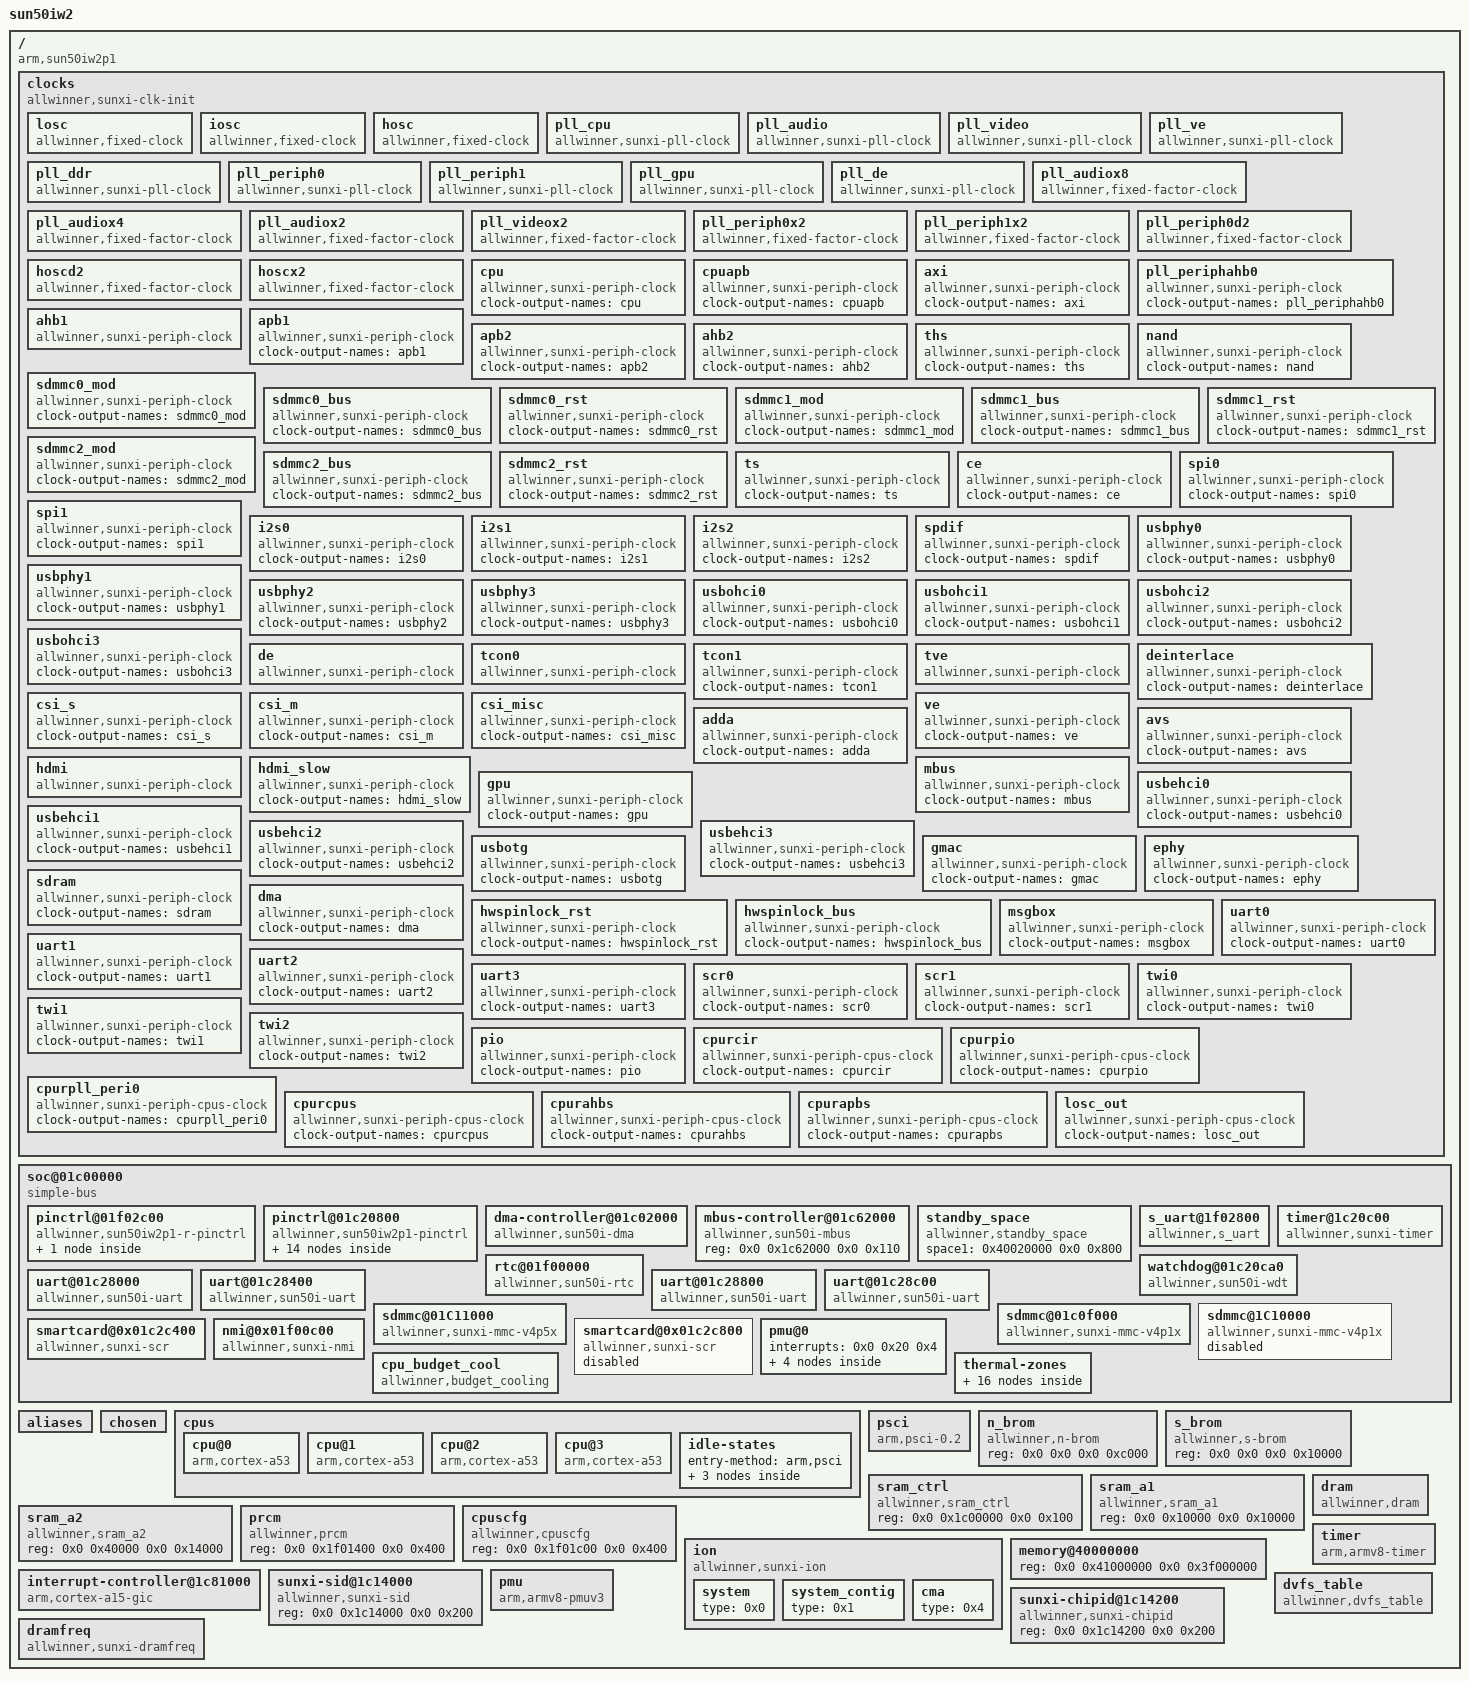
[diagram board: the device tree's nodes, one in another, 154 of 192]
/dts-v1/;

/memreserve/	0x0000000040020000 0x0000000000000800;
/memreserve/	0x0000000048000000 0x0000000001000000;
/memreserve/	0x0000000048100000 0x0000000000004000;
/memreserve/	0x0000000048104000 0x0000000000001000;
/memreserve/	0x0000000048105000 0x0000000000001000;
/ {
	model = "sun50iw2";
	compatible = "arm,sun50iw2p1";
	interrupt-parent = <0x1>;
	#address-cells = <0x2>;
	#size-cells = <0x2>;

	clocks {
		compatible = "allwinner,sunxi-clk-init";
		device_type = "clocks";
		#address-cells = <0x2>;
		#size-cells = <0x2>;
		ranges;
		reg = <0x0 0x1c20000 0x0 0x324 0x0 0x1f01400 0x0 0x1d4 0x0 0x1f00060 0x0 0x4>;

		losc {
			#clock-cells = <0x0>;
			compatible = "allwinner,fixed-clock";
			clock-frequency = <0x8000>;
			clock-output-names = "losc";
			linux,phandle = <0xb>;
			phandle = <0xb>;
		};

		iosc {
			#clock-cells = <0x0>;
			compatible = "allwinner,fixed-clock";
			clock-frequency = <0xf42400>;
			clock-output-names = "iosc";
			linux,phandle = <0xc>;
			phandle = <0xc>;
		};

		hosc {
			#clock-cells = <0x0>;
			compatible = "allwinner,fixed-clock";
			clock-frequency = <0x16e3600>;
			clock-output-names = "hosc";
			linux,phandle = <0x6>;
			phandle = <0x6>;
		};

		pll_cpu {
			#clock-cells = <0x0>;
			compatible = "allwinner,sunxi-pll-clock";
			lock-mode = "none";
			clock-output-names = "pll_cpu";
		};

		pll_audio {
			#clock-cells = <0x0>;
			compatible = "allwinner,sunxi-pll-clock";
			lock-mode = "none";
			assigned-clock-rates = <0x1770000>;
			clock-output-names = "pll_audio";
			linux,phandle = <0x2>;
			phandle = <0x2>;
		};

		pll_video {
			#clock-cells = <0x0>;
			compatible = "allwinner,sunxi-pll-clock";
			lock-mode = "none";
			assigned-clock-rates = <0x11b3dc40>;
			clock-output-names = "pll_video";
			linux,phandle = <0x3>;
			phandle = <0x3>;
		};

		pll_ve {
			#clock-cells = <0x0>;
			compatible = "allwinner,sunxi-pll-clock";
			device_type = "clk_pll_ve";
			lock-mode = "none";
			assigned-clock-rates = <0x1908b100>;
			clock-output-names = "pll_ve";
			linux,phandle = <0x15>;
			phandle = <0x15>;
		};

		pll_ddr {
			#clock-cells = <0x0>;
			compatible = "allwinner,sunxi-pll-clock";
			lock-mode = "none";
			clock-output-names = "pll_ddr";
			linux,phandle = <0x99>;
			phandle = <0x99>;
		};

		pll_periph0 {
			#clock-cells = <0x0>;
			compatible = "allwinner,sunxi-pll-clock";
			lock-mode = "none";
			clock-output-names = "pll_periph0";
			linux,phandle = <0x4>;
			phandle = <0x4>;
		};

		pll_periph1 {
			#clock-cells = <0x0>;
			compatible = "allwinner,sunxi-pll-clock";
			lock-mode = "none";
			clock-output-names = "pll_periph1";
			linux,phandle = <0x5>;
			phandle = <0x5>;
		};

		pll_gpu {
			#clock-cells = <0x0>;
			compatible = "allwinner,sunxi-pll-clock";
			lock-mode = "none";
			clock-output-names = "pll_gpu";
		};

		pll_de {
			#clock-cells = <0x0>;
			compatible = "allwinner,sunxi-pll-clock";
			lock-mode = "none";
			assigned-clock-rates = <0x337f9800>;
			clock-output-names = "pll_de";
			linux,phandle = <0x7>;
			phandle = <0x7>;
		};

		pll_audiox8 {
			#clock-cells = <0x0>;
			compatible = "allwinner,fixed-factor-clock";
			clocks = <0x2>;
			clock-mult = <0x8>;
			clock-div = <0x1>;
			clock-output-names = "pll_audiox8";
		};

		pll_audiox4 {
			#clock-cells = <0x0>;
			compatible = "allwinner,fixed-factor-clock";
			clocks = <0x2>;
			clock-mult = <0x8>;
			clock-div = <0x2>;
			clock-output-names = "pll_audiox4";
		};

		pll_audiox2 {
			#clock-cells = <0x0>;
			compatible = "allwinner,fixed-factor-clock";
			clocks = <0x2>;
			clock-mult = <0x8>;
			clock-div = <0x4>;
			clock-output-names = "pll_audiox2";
		};

		pll_videox2 {
			#clock-cells = <0x0>;
			compatible = "allwinner,fixed-factor-clock";
			clocks = <0x3>;
			clock-mult = <0x2>;
			clock-div = <0x1>;
			clock-output-names = "pll_videox2";
		};

		pll_periph0x2 {
			#clock-cells = <0x0>;
			compatible = "allwinner,fixed-factor-clock";
			clocks = <0x4>;
			clock-mult = <0x2>;
			clock-div = <0x1>;
			clock-output-names = "pll_periph0x2";
		};

		pll_periph1x2 {
			#clock-cells = <0x0>;
			compatible = "allwinner,fixed-factor-clock";
			clocks = <0x5>;
			clock-mult = <0x2>;
			clock-div = <0x1>;
			clock-output-names = "pll_periph1x2";
			linux,phandle = <0x52>;
			phandle = <0x52>;
		};

		pll_periph0d2 {
			#clock-cells = <0x0>;
			compatible = "allwinner,fixed-factor-clock";
			clocks = <0x4>;
			clock-mult = <0x1>;
			clock-div = <0x2>;
			clock-output-names = "pll_periph0d2";
		};

		hoscd2 {
			#clock-cells = <0x0>;
			compatible = "allwinner,fixed-factor-clock";
			clocks = <0x6>;
			clock-mult = <0x1>;
			clock-div = <0x2>;
			clock-output-names = "hoscd2";
		};

		hoscx2 {
			#clock-cells = <0x0>;
			compatible = "allwinner,fixed-factor-clock";
			clocks = <0x6>;
			clock-mult = <0x2>;
			clock-div = <0x1>;
			clock-output-names = "hoscx2";
		};

		cpu {
			#clock-cells = <0x0>;
			compatible = "allwinner,sunxi-periph-clock";
			clock-output-names = "cpu";
		};

		cpuapb {
			#clock-cells = <0x0>;
			compatible = "allwinner,sunxi-periph-clock";
			clock-output-names = "cpuapb";
		};

		axi {
			#clock-cells = <0x0>;
			compatible = "allwinner,sunxi-periph-clock";
			clock-output-names = "axi";
		};

		pll_periphahb0 {
			#clock-cells = <0x0>;
			compatible = "allwinner,sunxi-periph-clock";
			clock-output-names = "pll_periphahb0";
		};

		ahb1 {
			#clock-cells = <0x0>;
			assigned-clock-rates = <0xbebc200>;
			compatible = "allwinner,sunxi-periph-clock";
			clock-output-names = "ahb1";
			linux,phandle = <0x9a>;
			phandle = <0x9a>;
		};

		apb1 {
			#clock-cells = <0x0>;
			compatible = "allwinner,sunxi-periph-clock";
			clock-output-names = "apb1";
		};

		apb2 {
			#clock-cells = <0x0>;
			compatible = "allwinner,sunxi-periph-clock";
			clock-output-names = "apb2";
			linux,phandle = <0x74>;
			phandle = <0x74>;
		};

		ahb2 {
			#clock-cells = <0x0>;
			compatible = "allwinner,sunxi-periph-clock";
			clock-output-names = "ahb2";
		};

		ths {
			#clock-cells = <0x0>;
			compatible = "allwinner,sunxi-periph-clock";
			clock-output-names = "ths";
			linux,phandle = <0x89>;
			phandle = <0x89>;
		};

		nand {
			#clock-cells = <0x0>;
			compatible = "allwinner,sunxi-periph-clock";
			clock-output-names = "nand";
			linux,phandle = <0x7c>;
			phandle = <0x7c>;
		};

		sdmmc0_mod {
			#clock-cells = <0x0>;
			compatible = "allwinner,sunxi-periph-clock";
			clock-output-names = "sdmmc0_mod";
			linux,phandle = <0x58>;
			phandle = <0x58>;
		};

		sdmmc0_bus {
			#clock-cells = <0x0>;
			compatible = "allwinner,sunxi-periph-clock";
			clock-output-names = "sdmmc0_bus";
			linux,phandle = <0x59>;
			phandle = <0x59>;
		};

		sdmmc0_rst {
			#clock-cells = <0x0>;
			compatible = "allwinner,sunxi-periph-clock";
			clock-output-names = "sdmmc0_rst";
			linux,phandle = <0x5a>;
			phandle = <0x5a>;
		};

		sdmmc1_mod {
			#clock-cells = <0x0>;
			compatible = "allwinner,sunxi-periph-clock";
			clock-output-names = "sdmmc1_mod";
			linux,phandle = <0x5e>;
			phandle = <0x5e>;
		};

		sdmmc1_bus {
			#clock-cells = <0x0>;
			compatible = "allwinner,sunxi-periph-clock";
			clock-output-names = "sdmmc1_bus";
			linux,phandle = <0x5f>;
			phandle = <0x5f>;
		};

		sdmmc1_rst {
			#clock-cells = <0x0>;
			compatible = "allwinner,sunxi-periph-clock";
			clock-output-names = "sdmmc1_rst";
			linux,phandle = <0x60>;
			phandle = <0x60>;
		};

		sdmmc2_mod {
			#clock-cells = <0x0>;
			compatible = "allwinner,sunxi-periph-clock";
			clock-output-names = "sdmmc2_mod";
			linux,phandle = <0x53>;
			phandle = <0x53>;
		};

		sdmmc2_bus {
			#clock-cells = <0x0>;
			compatible = "allwinner,sunxi-periph-clock";
			clock-output-names = "sdmmc2_bus";
			linux,phandle = <0x54>;
			phandle = <0x54>;
		};

		sdmmc2_rst {
			#clock-cells = <0x0>;
			compatible = "allwinner,sunxi-periph-clock";
			clock-output-names = "sdmmc2_rst";
			linux,phandle = <0x55>;
			phandle = <0x55>;
		};

		ts {
			#clock-cells = <0x0>;
			compatible = "allwinner,sunxi-periph-clock";
			clock-output-names = "ts";
			linux,phandle = <0x80>;
			phandle = <0x80>;
		};

		ce {
			#clock-cells = <0x0>;
			compatible = "allwinner,sunxi-periph-clock";
			clock-output-names = "ce";
			linux,phandle = <0x71>;
			phandle = <0x71>;
		};

		spi0 {
			#clock-cells = <0x0>;
			compatible = "allwinner,sunxi-periph-clock";
			clock-output-names = "spi0";
			linux,phandle = <0x4a>;
			phandle = <0x4a>;
		};

		spi1 {
			#clock-cells = <0x0>;
			compatible = "allwinner,sunxi-periph-clock";
			clock-output-names = "spi1";
			linux,phandle = <0x4e>;
			phandle = <0x4e>;
		};

		i2s0 {
			#clock-cells = <0x0>;
			compatible = "allwinner,sunxi-periph-clock";
			clock-output-names = "i2s0";
			linux,phandle = <0x3a>;
			phandle = <0x3a>;
		};

		i2s1 {
			#clock-cells = <0x0>;
			compatible = "allwinner,sunxi-periph-clock";
			clock-output-names = "i2s1";
			linux,phandle = <0x3f>;
			phandle = <0x3f>;
		};

		i2s2 {
			#clock-cells = <0x0>;
			compatible = "allwinner,sunxi-periph-clock";
			clock-output-names = "i2s2";
			linux,phandle = <0x40>;
			phandle = <0x40>;
		};

		spdif {
			#clock-cells = <0x0>;
			compatible = "allwinner,sunxi-periph-clock";
			clock-output-names = "spdif";
			linux,phandle = <0x41>;
			phandle = <0x41>;
		};

		usbphy0 {
			#clock-cells = <0x0>;
			compatible = "allwinner,sunxi-periph-clock";
			clock-output-names = "usbphy0";
			linux,phandle = <0x2c>;
			phandle = <0x2c>;
		};

		usbphy1 {
			#clock-cells = <0x0>;
			compatible = "allwinner,sunxi-periph-clock";
			clock-output-names = "usbphy1";
			linux,phandle = <0x30>;
			phandle = <0x30>;
		};

		usbphy2 {
			#clock-cells = <0x0>;
			compatible = "allwinner,sunxi-periph-clock";
			clock-output-names = "usbphy2";
			linux,phandle = <0x33>;
			phandle = <0x33>;
		};

		usbphy3 {
			#clock-cells = <0x0>;
			compatible = "allwinner,sunxi-periph-clock";
			clock-output-names = "usbphy3";
			linux,phandle = <0x36>;
			phandle = <0x36>;
		};

		usbohci0 {
			#clock-cells = <0x0>;
			compatible = "allwinner,sunxi-periph-clock";
			clock-output-names = "usbohci0";
			linux,phandle = <0x2f>;
			phandle = <0x2f>;
		};

		usbohci1 {
			#clock-cells = <0x0>;
			compatible = "allwinner,sunxi-periph-clock";
			clock-output-names = "usbohci1";
			linux,phandle = <0x32>;
			phandle = <0x32>;
		};

		usbohci2 {
			#clock-cells = <0x0>;
			compatible = "allwinner,sunxi-periph-clock";
			clock-output-names = "usbohci2";
			linux,phandle = <0x35>;
			phandle = <0x35>;
		};

		usbohci3 {
			#clock-cells = <0x0>;
			compatible = "allwinner,sunxi-periph-clock";
			clock-output-names = "usbohci3";
			linux,phandle = <0x38>;
			phandle = <0x38>;
		};

		de {
			#clock-cells = <0x0>;
			compatible = "allwinner,sunxi-periph-clock";
			assigned-clock-parents = <0x7>;
			assigned-clock-rates = <0x19bfcc00>;
			clock-output-names = "de";
			linux,phandle = <0x63>;
			phandle = <0x63>;
		};

		tcon0 {
			#clock-cells = <0x0>;
			compatible = "allwinner,sunxi-periph-clock";
			assigned-clock-parents = <0x3>;
			clock-output-names = "tcon0";
			linux,phandle = <0x64>;
			phandle = <0x64>;
		};

		tcon1 {
			#clock-cells = <0x0>;
			compatible = "allwinner,sunxi-periph-clock";
			clock-output-names = "tcon1";
			linux,phandle = <0x65>;
			phandle = <0x65>;
		};

		tve {
			#clock-cells = <0x0>;
			compatible = "allwinner,sunxi-periph-clock";
			assigned-clock-parents = <0x7>;
			clock-output-names = "tve";
			linux,phandle = <0x68>;
			phandle = <0x68>;
		};

		deinterlace {
			#clock-cells = <0x0>;
			compatible = "allwinner,sunxi-periph-clock";
			clock-output-names = "deinterlace";
			linux,phandle = <0x72>;
			phandle = <0x72>;
		};

		csi_s {
			#clock-cells = <0x0>;
			compatible = "allwinner,sunxi-periph-clock";
			clock-output-names = "csi_s";
			linux,phandle = <0x6b>;
			phandle = <0x6b>;
		};

		csi_m {
			#clock-cells = <0x0>;
			compatible = "allwinner,sunxi-periph-clock";
			clock-output-names = "csi_m";
			linux,phandle = <0x6c>;
			phandle = <0x6c>;
		};

		csi_misc {
			#clock-cells = <0x0>;
			compatible = "allwinner,sunxi-periph-clock";
			clock-output-names = "csi_misc";
			linux,phandle = <0x6d>;
			phandle = <0x6d>;
		};

		ve {
			#clock-cells = <0x0>;
			compatible = "allwinner,sunxi-periph-clock";
			clock-output-names = "ve";
			linux,phandle = <0x16>;
			phandle = <0x16>;
		};

		adda {
			#clock-cells = <0x0>;
			compatible = "allwinner,sunxi-periph-clock";
			clock-output-names = "adda";
			linux,phandle = <0x39>;
			phandle = <0x39>;
		};

		avs {
			#clock-cells = <0x0>;
			compatible = "allwinner,sunxi-periph-clock";
			clock-output-names = "avs";
		};

		hdmi {
			#clock-cells = <0x0>;
			compatible = "allwinner,sunxi-periph-clock";
			assigned-clock-parents = <0x3>;
			clock-output-names = "hdmi";
			linux,phandle = <0x66>;
			phandle = <0x66>;
		};

		hdmi_slow {
			#clock-cells = <0x0>;
			compatible = "allwinner,sunxi-periph-clock";
			clock-output-names = "hdmi_slow";
			linux,phandle = <0x67>;
			phandle = <0x67>;
		};

		mbus {
			#clock-cells = <0x0>;
			compatible = "allwinner,sunxi-periph-clock";
			clock-output-names = "mbus";
		};

		gpu {
			#clock-cells = <0x0>;
			compatible = "allwinner,sunxi-periph-clock";
			clock-output-names = "gpu";
		};

		usbehci0 {
			#clock-cells = <0x0>;
			compatible = "allwinner,sunxi-periph-clock";
			clock-output-names = "usbehci0";
			linux,phandle = <0x2e>;
			phandle = <0x2e>;
		};

		usbehci1 {
			#clock-cells = <0x0>;
			compatible = "allwinner,sunxi-periph-clock";
			clock-output-names = "usbehci1";
			linux,phandle = <0x31>;
			phandle = <0x31>;
		};

		usbehci2 {
			#clock-cells = <0x0>;
			compatible = "allwinner,sunxi-periph-clock";
			clock-output-names = "usbehci2";
			linux,phandle = <0x34>;
			phandle = <0x34>;
		};

		usbehci3 {
			#clock-cells = <0x0>;
			compatible = "allwinner,sunxi-periph-clock";
			clock-output-names = "usbehci3";
			linux,phandle = <0x37>;
			phandle = <0x37>;
		};

		usbotg {
			#clock-cells = <0x0>;
			compatible = "allwinner,sunxi-periph-clock";
			clock-output-names = "usbotg";
			linux,phandle = <0x2d>;
			phandle = <0x2d>;
		};

		gmac {
			#clock-cells = <0x0>;
			compatible = "allwinner,sunxi-periph-clock";
			clock-output-names = "gmac";
			linux,phandle = <0x94>;
			phandle = <0x94>;
		};

		ephy {
			#clock-cells = <0x0>;
			compatible = "allwinner,sunxi-periph-clock";
			clock-output-names = "ephy";
			linux,phandle = <0x95>;
			phandle = <0x95>;
		};

		sdram {
			#clock-cells = <0x0>;
			compatible = "allwinner,sunxi-periph-clock";
			clock-output-names = "sdram";
		};

		dma {
			#clock-cells = <0x0>;
			compatible = "allwinner,sunxi-periph-clock";
			clock-output-names = "dma";
			linux,phandle = <0xa>;
			phandle = <0xa>;
		};

		hwspinlock_rst {
			#clock-cells = <0x0>;
			compatible = "allwinner,sunxi-periph-clock";
			clock-output-names = "hwspinlock_rst";
			linux,phandle = <0xe>;
			phandle = <0xe>;
		};

		hwspinlock_bus {
			#clock-cells = <0x0>;
			compatible = "allwinner,sunxi-periph-clock";
			clock-output-names = "hwspinlock_bus";
			linux,phandle = <0xf>;
			phandle = <0xf>;
		};

		msgbox {
			#clock-cells = <0x0>;
			compatible = "allwinner,sunxi-periph-clock";
			clock-output-names = "msgbox";
			linux,phandle = <0xd>;
			phandle = <0xd>;
		};

		uart0 {
			#clock-cells = <0x0>;
			compatible = "allwinner,sunxi-periph-clock";
			clock-output-names = "uart0";
			linux,phandle = <0x17>;
			phandle = <0x17>;
		};

		uart1 {
			#clock-cells = <0x0>;
			compatible = "allwinner,sunxi-periph-clock";
			clock-output-names = "uart1";
			linux,phandle = <0x1a>;
			phandle = <0x1a>;
		};

		uart2 {
			#clock-cells = <0x0>;
			compatible = "allwinner,sunxi-periph-clock";
			clock-output-names = "uart2";
			linux,phandle = <0x1d>;
			phandle = <0x1d>;
		};

		uart3 {
			#clock-cells = <0x0>;
			compatible = "allwinner,sunxi-periph-clock";
			clock-output-names = "uart3";
			linux,phandle = <0x20>;
			phandle = <0x20>;
		};

		scr0 {
			#clock-cells = <0x0>;
			compatible = "allwinner,sunxi-periph-clock";
			clock-output-names = "scr0";
			linux,phandle = <0x73>;
			phandle = <0x73>;
		};

		scr1 {
			#clock-cells = <0x0>;
			compatible = "allwinner,sunxi-periph-clock";
			clock-output-names = "scr1";
			linux,phandle = <0x78>;
			phandle = <0x78>;
		};

		twi0 {
			#clock-cells = <0x0>;
			compatible = "allwinner,sunxi-periph-clock";
			clock-output-names = "twi0";
			linux,phandle = <0x23>;
			phandle = <0x23>;
		};

		twi1 {
			#clock-cells = <0x0>;
			compatible = "allwinner,sunxi-periph-clock";
			clock-output-names = "twi1";
			linux,phandle = <0x26>;
			phandle = <0x26>;
		};

		twi2 {
			#clock-cells = <0x0>;
			compatible = "allwinner,sunxi-periph-clock";
			clock-output-names = "twi2";
			linux,phandle = <0x29>;
			phandle = <0x29>;
		};

		pio {
			#clock-cells = <0x0>;
			compatible = "allwinner,sunxi-periph-clock";
			clock-output-names = "pio";
			linux,phandle = <0x9>;
			phandle = <0x9>;
		};

		cpurcir {
			#clock-cells = <0x0>;
			compatible = "allwinner,sunxi-periph-cpus-clock";
			clock-output-names = "cpurcir";
			linux,phandle = <0x11>;
			phandle = <0x11>;
		};

		cpurpio {
			#clock-cells = <0x0>;
			compatible = "allwinner,sunxi-periph-cpus-clock";
			clock-output-names = "cpurpio";
			linux,phandle = <0x8>;
			phandle = <0x8>;
		};

		cpurpll_peri0 {
			#clock-cells = <0x0>;
			compatible = "allwinner,sunxi-periph-cpus-clock";
			clock-output-names = "cpurpll_peri0";
		};

		cpurcpus {
			#clock-cells = <0x0>;
			compatible = "allwinner,sunxi-periph-cpus-clock";
			clock-output-names = "cpurcpus";
		};

		cpurahbs {
			#clock-cells = <0x0>;
			compatible = "allwinner,sunxi-periph-cpus-clock";
			clock-output-names = "cpurahbs";
		};

		cpurapbs {
			#clock-cells = <0x0>;
			compatible = "allwinner,sunxi-periph-cpus-clock";
			clock-output-names = "cpurapbs";
		};

		losc_out {
			#clock-cells = <0x0>;
			compatible = "allwinner,sunxi-periph-cpus-clock";
			clock-output-names = "losc_out";
			linux,phandle = <0x9b>;
			phandle = <0x9b>;
		};
	};

	soc@01c00000 {
		compatible = "simple-bus";
		#address-cells = <0x2>;
		#size-cells = <0x2>;
		ranges;
		device_type = "soc";

		pinctrl@01f02c00 {
			compatible = "allwinner,sun50iw2p1-r-pinctrl";
			reg = <0x0 0x1f02c00 0x0 0x400>;
			interrupts = <0x0 0x2d 0x4>;
			clocks = <0x8>;
			device_type = "r_pio";
			gpio-controller;
			interrupt-controller;
			#interrupt-cells = <0x2>;
			#size-cells = <0x0>;
			#gpio-cells = <0x6>;
			linux,phandle = <0x9c>;
			phandle = <0x9c>;

			s_uart0@0 {
				allwinner,pins = "PL2", "PL3";
				allwinner,function = "s_uart0";
				allwinner,muxsel = <0x2>;
				allwinner,drive = <0x1>;
				allwinner,pull = <0x1>;
				linux,phandle = <0x12>;
				phandle = <0x12>;
			};
		};

		pinctrl@01c20800 {
			compatible = "allwinner,sun50iw2p1-pinctrl";
			reg = <0x0 0x1c20800 0x0 0x400>;
			interrupts = <0x0 0xb 0x4 0x0 0x11 0x4 0x0 0x17 0x4>;
			device_type = "pio";
			clocks = <0x9>;
			gpio-controller;
			interrupt-controller;
			#interrupt-cells = <0x2>;
			#size-cells = <0x0>;
			#gpio-cells = <0x6>;
			linux,phandle = <0x5d>;
			phandle = <0x5d>;

			uart0@0 {
				allwinner,pins = "PA4", "PA5";
				allwinner,pname = "uart0_tx", "uart0_rx";
				allwinner,function = "uart0";
				allwinner,muxsel = <0x2>;
				allwinner,drive = <0x1>;
				allwinner,pull = <0x1>;
				linux,phandle = <0x18>;
				phandle = <0x18>;
			};

			uart0@1 {
				allwinner,pins = "PA4", "PA5";
				allwinner,function = "io_disabled";
				allwinner,muxsel = <0x7>;
				allwinner,drive = <0x1>;
				allwinner,pull = <0x0>;
				linux,phandle = <0x19>;
				phandle = <0x19>;
			};

			uart1@0 {
				allwinner,pins = "PG6", "PG7", "PG8", "PG9";
				allwinner,pname = "uart1_tx", "uart1_rx", "uart1_rts", "uart1_cts";
				allwinner,function = "uart1";
				allwinner,muxsel = <0x2>;
				allwinner,drive = <0x1>;
				allwinner,pull = <0x1>;
				linux,phandle = <0x1b>;
				phandle = <0x1b>;
			};

			uart1@1 {
				allwinner,pins = "PG6", "PG7", "PG8", "PG9";
				allwinner,function = "io_disabled";
				allwinner,muxsel = <0x7>;
				allwinner,drive = <0x1>;
				allwinner,pull = <0x0>;
				linux,phandle = <0x1c>;
				phandle = <0x1c>;
			};

			uart2@0 {
				allwinner,pins = "PA0", "PA1", "PA2", "PA3";
				allwinner,pname = "uart2_tx", "uart2_rx", "uart2_rts", "uart2_cts";
				allwinner,function = "uart2";
				allwinner,muxsel = <0x2>;
				allwinner,drive = <0x1>;
				allwinner,pull = <0x1>;
				linux,phandle = <0x1e>;
				phandle = <0x1e>;
			};

			uart2@1 {
				allwinner,pins = "PA0", "PA1", "PA2", "PA3";
				allwinner,function = "io_disabled";
				allwinner,muxsel = <0x7>;
				allwinner,drive = <0x1>;
				allwinner,pull = <0x0>;
				linux,phandle = <0x1f>;
				phandle = <0x1f>;
			};

			uart3@0 {
				allwinner,pins = "PA13", "PA14";
				allwinner,pname = "uart3_tx", "uart3_rx";
				allwinner,function = "uart3";
				allwinner,muxsel = <0x3>;
				allwinner,drive = <0x1>;
				allwinner,pull = <0x1>;
				linux,phandle = <0x21>;
				phandle = <0x21>;
			};

			uart3@1 {
				allwinner,pins = "PA13", "PA14", "PA15", "PA16";
				allwinner,function = "io_disabled";
				allwinner,muxsel = <0x7>;
				allwinner,drive = <0x1>;
				allwinner,pull = <0x0>;
				linux,phandle = <0x22>;
				phandle = <0x22>;
			};

			sdc0@0 {
				allwinner,pins = "PF0", "PF1", "PF2", "PF3", "PF4", "PF5";
				allwinner,function = "sdc0";
				allwinner,muxsel = <0x2>;
				allwinner,drive = <0x1>;
				allwinner,pull = <0x1>;
				linux,phandle = <0x5b>;
				phandle = <0x5b>;
			};

			sdc0@1 {
				allwinner,pins = "PF0", "PF1", "PF2", "PF3", "PF4", "PF5";
				allwinner,function = "io_disabled";
				allwinner,muxsel = <0x7>;
				allwinner,drive = <0x1>;
				allwinner,pull = <0x1>;
				linux,phandle = <0x5c>;
				phandle = <0x5c>;
			};

			sdc1@0 {
				allwinner,pins = "PG0", "PG1", "PG2", "PG3", "PG4", "PG5";
				allwinner,function = "sdc1";
				allwinner,muxsel = <0x2>;
				allwinner,drive = <0x3>;
				allwinner,pull = <0x1>;
				linux,phandle = <0x61>;
				phandle = <0x61>;
			};

			sdc1@1 {
				allwinner,pins = "PG0", "PG1", "PG2", "PG3", "PG4", "PG5";
				allwinner,function = "io_disabled";
				allwinner,muxsel = <0x7>;
				allwinner,drive = <0x1>;
				allwinner,pull = <0x1>;
				linux,phandle = <0x62>;
				phandle = <0x62>;
			};

			sdc2@0 {
				allwinner,pins = "PC1", "PC5", "PC6", "PC8", "PC9", "PC10", "PC11", "PC12", "PC13", "PC14", "PC15", "PC16";
				allwinner,function = "sdc2";
				allwinner,muxsel = <0x3>;
				allwinner,drive = <0x2>;
				allwinner,pull = <0x1>;
				linux,phandle = <0x56>;
				phandle = <0x56>;
			};

			sdc2@1 {
				allwinner,pins = "PC1", "PC5", "PC6", "PC8", "PC9", "PC10", "PC11", "PC12", "PC13", "PC14", "PC15", "PC16";
				allwinner,function = "io_disabled";
				allwinner,muxsel = <0x7>;
				allwinner,drive = <0x1>;
				allwinner,pull = <0x1>;
				linux,phandle = <0x57>;
				phandle = <0x57>;
			};
		};

		dma-controller@01c02000 {
			compatible = "allwinner,sun50i-dma";
			reg = <0x0 0x1c02000 0x0 0x1000>;
			interrupts = <0x0 0x32 0x4>;
			clocks = <0xa>;
			#dma-cells = <0x1>;
		};

		mbus-controller@01c62000 {
			compatible = "allwinner,sun50i-mbus";
			reg = <0x0 0x1c62000 0x0 0x110>;
			#mbus-cells = <0x1>;
		};

		standby_space {
			compatible = "allwinner,standby_space";
			space1 = <0x40020000 0x0 0x800>;
		};

		s_uart@1f02800 {
			compatible = "allwinner,s_uart";
			reg = <0x0 0x1f02800 0x0 0x400>;
			interrupts = <0x0 0x26 0x4>;
			pinctrl-names = "default";
			pinctrl-0 = <0x12>;
			status = "okay";
		};

		timer@1c20c00 {
			compatible = "allwinner,sunxi-timer";
			device_type = "timer";
			reg = <0x0 0x1c20c00 0x0 0x90>;
			interrupts = <0x0 0x12 0x1>;
			clock-frequency = <0x16e3600>;
			timer-prescale = <0x10>;
		};

		rtc@01f00000 {
			compatible = "allwinner,sun50i-rtc";
			device_type = "rtc";
			reg = <0x0 0x1f00000 0x0 0x218>;
			interrupts = <0x0 0x28 0x4>;
			gpr_offset = <0x100>;
			gpr_len = <0x4>;
		};

		watchdog@01c20ca0 {
			compatible = "allwinner,sun50i-wdt";
			reg = <0x0 0x1c20ca0 0x0 0x20>;
			interrupts = <0x0 0x19 0x4>;
		};

		uart@01c28000 {
			compatible = "allwinner,sun50i-uart";
			device_type = "uart0";
			reg = <0x0 0x1c28000 0x0 0x400>;
			interrupts = <0x0 0x0 0x4>;
			clocks = <0x17>;
			pinctrl-names = "default", "sleep";
			pinctrl-0 = <0x18>;
			pinctrl-1 = <0x19>;
			uart0_port = <0x0>;
			uart0_type = <0x2>;
			status = "okay";
		};

		uart@01c28400 {
			compatible = "allwinner,sun50i-uart";
			device_type = "uart1";
			reg = <0x0 0x1c28400 0x0 0x400>;
			interrupts = <0x0 0x1 0x4>;
			clocks = <0x1a>;
			pinctrl-names = "default", "sleep";
			pinctrl-0 = <0x1b>;
			pinctrl-1 = <0x1c>;
			uart1_port = <0x1>;
			uart1_type = <0x4>;
			status = "okay";
		};

		uart@01c28800 {
			compatible = "allwinner,sun50i-uart";
			device_type = "uart2";
			reg = <0x0 0x1c28800 0x0 0x400>;
			interrupts = <0x0 0x2 0x4>;
			clocks = <0x1d>;
			pinctrl-names = "default", "sleep";
			pinctrl-0 = <0x1e>;
			pinctrl-1 = <0x1f>;
			uart2_port = <0x2>;
			uart2_type = <0x4>;
			status = "okay";
		};

		uart@01c28c00 {
			compatible = "allwinner,sun50i-uart";
			device_type = "uart3";
			reg = <0x0 0x1c28c00 0x0 0x400>;
			interrupts = <0x0 0x3 0x4>;
			clocks = <0x20>;
			pinctrl-names = "default", "sleep";
			pinctrl-0 = <0x21>;
			pinctrl-1 = <0x22>;
			uart3_port = <0x3>;
			uart3_type = <0x4>;
			status = "okay";
		};

		sdmmc@01C11000 {
			compatible = "allwinner,sunxi-mmc-v4p5x";
			device_type = "sdc2";
			boot_device = <0x0>;
			reg = <0x0 0x1c11000 0x0 0x1000>;
			interrupts = <0x0 0x3e 0x104>;
			clocks = <0x6 0x52 0x53 0x54 0x55>;
			clock-names = "osc24m", "pll_periph", "mmc", "ahb", "rst";
			pinctrl-names = "default", "sleep";
			pinctrl-0 = <0x56>;
			pinctrl-1 = <0x57>;
			bus-width = <0x8>;
			max-frequency = <0x2faf080>;
			sdc_tm4_sm0_freq0 = <0x0>;
			sdc_tm4_sm0_freq1 = <0x0>;
			sdc_tm4_sm1_freq0 = <0x0>;
			sdc_tm4_sm1_freq1 = <0x0>;
			sdc_tm4_sm2_freq0 = <0x0>;
			sdc_tm4_sm2_freq1 = <0x0>;
			sdc_tm4_sm3_freq0 = <0x5000000>;
			sdc_tm4_sm3_freq1 = <0x5>;
			sdc_tm4_sm4_freq0 = <0x50000>;
			sdc_tm4_sm4_freq1 = <0x4>;
			status = "okay";
		};

		sdmmc@01c0f000 {
			compatible = "allwinner,sunxi-mmc-v4p1x";
			device_type = "sdc0";
			boot_device = <0x0>;
			reg = <0x0 0x1c0f000 0x0 0x1000>;
			interrupts = <0x0 0x3c 0x104>;
			clocks = <0x6 0x52 0x58 0x59 0x5a>;
			clock-names = "osc24m", "pll_periph", "mmc", "ahb", "rst";
			pinctrl-names = "default", "sleep";
			pinctrl-0 = <0x5b>;
			pinctrl-1 = <0x5c>;
			max-frequency = <0x2faf080>;
			bus-width = <0x4>;
			cd-gpios = <0x5d 0x5 0x6 0x0 0x1 0x2 0x0>;
			status = "okay";
		};

		sdmmc@1C10000 {
			compatible = "allwinner,sunxi-mmc-v4p1x";
			device_type = "sdc1";
			boot_device = <0x0>;
			reg = <0x0 0x1c10000 0x0 0x1000>;
			interrupts = <0x0 0x3d 0x104>;
			clocks = <0x6 0x52 0x5e 0x5f 0x60>;
			clock-names = "osc24m", "pll_periph", "mmc", "ahb", "rst";
			pinctrl-names = "default", "sleep";
			pinctrl-0 = <0x61>;
			pinctrl-1 = <0x62>;
			max-frequency = <0x2faf080>;
			bus-width = <0x4>;
			sunxi-dly-52M-ddr4 = <0x1 0x0 0x0 0x0 0x2>;
			sunxi-dly-104M = <0x1 0x0 0x0 0x0 0x1>;
			sunxi-dly-208M = <0x1 0x0 0x0 0x0 0x1>;
			status = "disabled";
		};

		smartcard@0x01c2c400 {
			#address-cells = <0x1>;
			#size-cells = <0x0>;
			compatible = "allwinner,sunxi-scr";
			device_type = "scr0";
			reg = <0x0 0x1c2c400 0x0 0x400>;
			interrupts = <0x0 0x53 0x4>;
			clocks = <0x73 0x74>;
			clock-frequency = <0x16e3600>;
			pinctrl-names = "default", "sleep";
			pinctrl-0 = <0x75 0x76>;
			pinctrl-1 = <0x77>;
			status = "okay";
		};

		smartcard@0x01c2c800 {
			#address-cells = <0x1>;
			#size-cells = <0x0>;
			compatible = "allwinner,sunxi-scr";
			device_type = "scr1";
			reg = <0x0 0x1c2c800 0x0 0x400>;
			interrupts = <0x0 0x59 0x4>;
			clocks = <0x78 0x74>;
			clock-frequency = <0x16e3600>;
			pinctrl-names = "default", "sleep";
			pinctrl-0 = <0x79 0x7a>;
			pinctrl-1 = <0x7b>;
			status = "disabled";
		};

		pmu@0 {
			interrupts = <0x0 0x20 0x4>;
			status = "okay";

			powerkey@0 {
				status = "okay";
			};

			regulator@0 {
				status = "okay";
			};

			axp_gpio@0 {
				gpio-controller;
				#size-cells = <0x0>;
				#gpio-cells = <0x6>;
				status = "disabled";
				device_type = "axp_pio";
			};

			charger@0 {
				status = "disabled";
			};
		};

		nmi@0x01f00c00 {
			#address-cells = <0x1>;
			#size-cells = <0x0>;
			compatible = "allwinner,sunxi-nmi";
			reg = <0x0 0x1f00c00 0x0 0x50>;
			nmi_irq_ctrl = <0xc>;
			nmi_irq_en = <0x40>;
			nmi_irq_status = <0x10>;
			nmi_irq_mask = <0x50>;
			status = "okay";
		};

		cpu_budget_cool {
			compatible = "allwinner,budget_cooling";
			#cooling-cells = <0x2>;
			status = "okay";
			state_cnt = <0x5>;
			cluster_num = <0x1>;
			state0 = <0xf6180 0x4>;
			state1 = <0xc7380 0x4>;
			state2 = <0xc7380 0x2>;
			state3 = <0x9e340 0x2>;
			state4 = <0x75300 0x1>;
			linux,phandle = <0x8c>;
			phandle = <0x8c>;
		};

		thermal-zones {

			soc_thermal {
				polling-delay-passive = <0x3e8>;
				polling-delay = <0x2710>;
				thermal-sensors = <0x8a 0x0>;

				trips {

					t0 {
						temperature = <0x3c>;
						type = "passive";
						hysteresis = <0x0>;
						linux,phandle = <0x8b>;
						phandle = <0x8b>;
					};

					t1 {
						temperature = <0x50>;
						type = "passive";
						hysteresis = <0x0>;
						linux,phandle = <0x8d>;
						phandle = <0x8d>;
					};

					t2 {
						temperature = <0x64>;
						type = "passive";
						hysteresis = <0x0>;
						linux,phandle = <0x8e>;
						phandle = <0x8e>;
					};

					t3 {
						temperature = <0x50>;
						type = "passive";
						hysteresis = <0x0>;
						linux,phandle = <0x8f>;
						phandle = <0x8f>;
					};

					t4 {
						temperature = <0x5a>;
						type = "passive";
						hysteresis = <0x0>;
						linux,phandle = <0x91>;
						phandle = <0x91>;
					};

					t5 {
						temperature = <0x64>;
						type = "passive";
						hysteresis = <0x0>;
						linux,phandle = <0x92>;
						phandle = <0x92>;
					};

					t6 {
						temperature = <0x73>;
						type = "critical";
						hysteresis = <0x0>;
					};
				};

				cooling-maps {

					bind0 {
						contribution = <0x0>;
						trip = <0x8b>;
						cooling-device = <0x8c 0x1 0x1>;
					};

					bind1 {
						contribution = <0x0>;
						trip = <0x8d>;
						cooling-device = <0x8c 0x2 0x2>;
					};

					bind2 {
						contribution = <0x0>;
						trip = <0x8e>;
						cooling-device = <0x8c 0x3 0x4>;
					};

					bind3 {
						contribution = <0x0>;
						trip = <0x8f>;
						cooling-device = <0x90 0x1 0x1>;
					};

					bind4 {
						contribution = <0x0>;
						trip = <0x91>;
						cooling-device = <0x90 0x2 0x2>;
					};

					bind5 {
						contribution = <0x0>;
						trip = <0x92>;
						cooling-device = <0x90 0x3 0x3>;
					};
				};
			};
		};
	};

	aliases {
		serial0 = "/soc@01c00000/uart@01c28000";
		serial1 = "/soc@01c00000/uart@01c28400";
		serial2 = "/soc@01c00000/uart@01c28800";
		serial3 = "/soc@01c00000/uart@01c28c00";
		mmc0 = "/soc@01c00000/sdmmc@01c0f000";
		mmc2 = "/soc@01c00000/sdmmc@01C11000";
	};

	chosen {
		bootargs = "earlyprintk=sunxi-uart,0x01c28000 loglevel=8 initcall_debug=1 console=ttyS0 init=/init";
		linux,initrd-start = <0x0 0x0>;
		linux,initrd-end = <0x0 0x0>;
	};

	cpus {
		#address-cells = <0x2>;
		#size-cells = <0x0>;

		cpu@0 {
			device_type = "cpu";
			compatible = "arm,cortex-a53", "arm,armv8";
			reg = <0x0 0x0>;
			enable-method = "psci";
			cpufreq_tbl = <0x3a980 0x75300 0x9e340 0xafc80 0xc7380 0xdea80 0xf6180 0x10d880 0x119400 0x124f80>;
			clock-latency = <0x1e8480>;
			clock-frequency = <0x3c14dc00>;
			cpu-idle-states = <0x96 0x97 0x98>;
		};

		cpu@1 {
			device_type = "cpu";
			compatible = "arm,cortex-a53", "arm,armv8";
			reg = <0x0 0x1>;
			enable-method = "psci";
			clock-frequency = <0x3c14dc00>;
			cpu-idle-states = <0x96 0x97 0x98>;
		};

		cpu@2 {
			device_type = "cpu";
			compatible = "arm,cortex-a53", "arm,armv8";
			reg = <0x0 0x2>;
			enable-method = "psci";
			clock-frequency = <0x3c14dc00>;
			cpu-idle-states = <0x96 0x97 0x98>;
		};

		cpu@3 {
			device_type = "cpu";
			compatible = "arm,cortex-a53", "arm,armv8";
			reg = <0x0 0x3>;
			enable-method = "psci";
			clock-frequency = <0x3c14dc00>;
			cpu-idle-states = <0x96 0x97 0x98>;
		};

		idle-states {
			entry-method = "arm,psci";

			cpu-sleep-0 {
				compatible = "arm,idle-state";
				arm,psci-suspend-param = <0x10000>;
				entry-latency-us = <0x28>;
				exit-latency-us = <0x64>;
				min-residency-us = <0x96>;
				linux,phandle = <0x96>;
				phandle = <0x96>;
			};

			cluster-sleep-0 {
				compatible = "arm,idle-state";
				arm,psci-suspend-param = <0x1010000>;
				entry-latency-us = <0x1f4>;
				exit-latency-us = <0x3e8>;
				min-residency-us = <0x9c4>;
				linux,phandle = <0x97>;
				phandle = <0x97>;
			};

			sys-sleep-0 {
				compatible = "arm,idle-state";
				arm,psci-suspend-param = <0x2010000>;
				entry-latency-us = <0x3e8>;
				exit-latency-us = <0x7d0>;
				min-residency-us = <0x1194>;
				linux,phandle = <0x98>;
				phandle = <0x98>;
			};
		};
	};

	psci {
		compatible = "arm,psci-0.2";
		method = "smc";
		psci_version = <0x84000000>;
		cpu_suspend = <0xc4000001>;
		cpu_off = <0x84000002>;
		cpu_on = <0xc4000003>;
		affinity_info = <0xc4000004>;
		migrate = <0xc4000005>;
		migrate_info_type = <0x84000006>;
		migrate_info_up_cpu = <0xc4000007>;
		system_off = <0x84000008>;
		system_reset = <0x84000009>;
	};

	n_brom {
		compatible = "allwinner,n-brom";
		reg = <0x0 0x0 0x0 0xc000>;
	};

	s_brom {
		compatible = "allwinner,s-brom";
		reg = <0x0 0x0 0x0 0x10000>;
	};

	sram_ctrl {
		device_type = "sram_ctrl";
		compatible = "allwinner,sram_ctrl";
		reg = <0x0 0x1c00000 0x0 0x100>;
	};

	sram_a1 {
		compatible = "allwinner,sram_a1";
		reg = <0x0 0x10000 0x0 0x10000>;
	};

	sram_a2 {
		compatible = "allwinner,sram_a2";
		reg = <0x0 0x40000 0x0 0x14000>;
	};

	prcm {
		compatible = "allwinner,prcm";
		reg = <0x0 0x1f01400 0x0 0x400>;
	};

	cpuscfg {
		compatible = "allwinner,cpuscfg";
		reg = <0x0 0x1f01c00 0x0 0x400>;
	};

	ion {
		compatible = "allwinner,sunxi-ion";

		system {
			type = <0x0>;
		};

		system_contig {
			type = <0x1>;
		};

		cma {
			type = <0x4>;
		};
	};

	dram {
		compatible = "allwinner,dram";
		clocks = <0x99>;
		clock-names = "pll_ddr";
		dram_clk = <0x2a0>;
		dram_type = <0x3>;
		dram_zq = <0x3f3fdd>;
		dram_odt_en = <0x1>;
		dram_para1 = <0x10f41000>;
		dram_para2 = <0x1200>;
		dram_mr0 = <0x1a50>;
		dram_mr1 = <0x40>;
		dram_mr2 = <0x10>;
		dram_mr3 = <0x0>;
		dram_tpr0 = <0x4e214ea>;
		dram_tpr1 = <0x4214ad>;
		dram_tpr2 = <0x10a75030>;
		dram_tpr3 = <0x0>;
		dram_tpr4 = <0x0>;
		dram_tpr5 = <0x0>;
		dram_tpr6 = <0x0>;
		dram_tpr7 = <0x0>;
		dram_tpr8 = <0x0>;
		dram_tpr9 = <0x0>;
		dram_tpr10 = <0x0>;
		dram_tpr11 = <0x0>;
		dram_tpr12 = <0xa8>;
		dram_tpr13 = <0x823>;
	};

	memory@40000000 {
		device_type = "memory";
		reg = <0x0 0x41000000 0x0 0x3f000000>;
	};

	interrupt-controller@1c81000 {
		compatible = "arm,cortex-a15-gic", "arm,cortex-a9-gic";
		#interrupt-cells = <0x3>;
		#address-cells = <0x0>;
		device_type = "gic";
		interrupt-controller;
		reg = <0x0 0x1c81000 0x0 0x1000 0x0 0x1c82000 0x0 0x2000 0x0 0x1c84000 0x0 0x2000 0x0 0x1c86000 0x0 0x2000>;
		interrupts = <0x1 0x9 0xf04>;
		linux,phandle = <0x1>;
		phandle = <0x1>;
	};

	sunxi-sid@1c14000 {
		compatible = "allwinner,sunxi-sid";
		device_type = "sid";
		reg = <0x0 0x1c14000 0x0 0x200>;
	};

	sunxi-chipid@1c14200 {
		compatible = "allwinner,sunxi-chipid";
		device_type = "chipid";
		reg = <0x0 0x1c14200 0x0 0x200>;
	};

	timer {
		compatible = "arm,armv8-timer";
		interrupts = <0x1 0xd 0xff01 0x1 0xe 0xff01 0x1 0xb 0xff01 0x1 0xa 0xff01>;
		clock-frequency = <0x16e3600>;
	};

	pmu {
		compatible = "arm,armv8-pmuv3";
		interrupts = <0x0 0x78 0x4 0x0 0x79 0x4 0x0 0x7a 0x4 0x0 0x7b 0x4>;
	};

	dvfs_table {
		compatible = "allwinner,dvfs_table";
		max_freq = <0x47868c00>;
		min_freq = <0x1c9c3800>;
		lv_count = <0x8>;
		lv1_freq = <0x47868c00>;
		lv1_volt = <0x514>;
		lv2_freq = <0x3c14dc00>;
		lv2_volt = <0x4b0>;
		lv3_freq = <0x30a32c00>;
		lv3_volt = <0x44c>;
		lv4_freq = <0x269fb200>;
		lv4_volt = <0x410>;
		lv5_freq = <0x0>;
		lv5_volt = <0x410>;
		lv6_freq = <0x0>;
		lv6_volt = <0x410>;
		lv7_freq = <0x0>;
		lv7_volt = <0x410>;
		lv8_freq = <0x0>;
		lv8_volt = <0x410>;
	};

	dramfreq {
		compatible = "allwinner,sunxi-dramfreq";
		reg = <0x0 0x1c62000 0x0 0x1000 0x0 0x1c63000 0x0 0x1000 0x0 0x1c20000 0x0 0x800>;
		interrupts = <0x0 0x45 0x4>;
		clocks = <0x99 0x4 0x9a>;
		status = "okay";
	};
};
